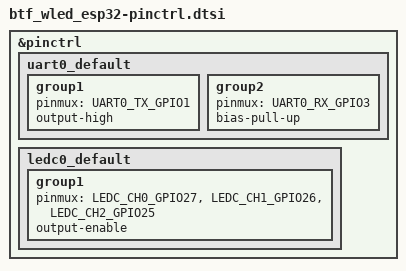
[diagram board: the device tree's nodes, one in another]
/*
 * SPDX-License-Identifier: Apache-2.0
 *
 * The three LED drive channels are numbered per the board silkscreen:
 * CH1=GPIO27, CH2=GPIO26, CH3=GPIO25. Each gate-drives a low-side 80N03
 * N-MOSFET through a 74HC245 buffer (non-inverting, so normal polarity).
 */

#include <zephyr/dt-bindings/pinctrl/esp-pinctrl-common.h>
#include <dt-bindings/pinctrl/esp32-pinctrl.h>
#include <zephyr/dt-bindings/pinctrl/esp32-gpio-sigmap.h>

&pinctrl {
	uart0_default: uart0_default {
		group1 {
			pinmux = <UART0_TX_GPIO1>;
			output-high;
		};

		group2 {
			pinmux = <UART0_RX_GPIO3>;
			bias-pull-up;
		};
	};

	ledc0_default: ledc0_default {
		group1 {
			pinmux = <LEDC_CH0_GPIO27>,
				 <LEDC_CH1_GPIO26>,
				 <LEDC_CH2_GPIO25>;
			output-enable;
		};
	};
};
